VERSION ""

NS_ :

BS_:

BU_: ECU_Engine ECU_Brake ECU_Gateway

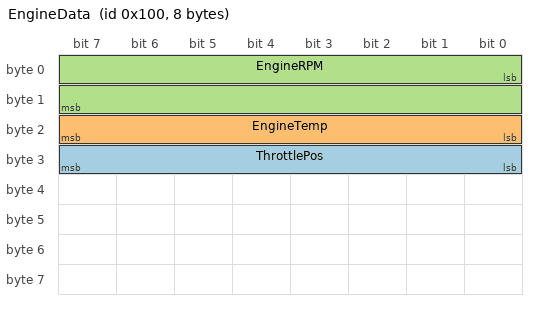
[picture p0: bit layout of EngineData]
BO_ 256 EngineData: 8 ECU_Engine
 SG_ ThrottlePos : 24|8@1+ (0.4,0) [0|100] "%"  ECU_Gateway
 SG_ EngineTemp : 16|8@1+ (1,-40) [-40|215] "degC"  ECU_Gateway
 SG_ EngineRPM : 0|16@1+ (0.25,0) [0|16000] "rpm"  ECU_Gateway

BO_ 512 VehicleSpeed: 8 ECU_Brake
 SG_ Speed : 0|16@1+ (0.01,0) [0|655.35] "km/h"  ECU_Gateway
